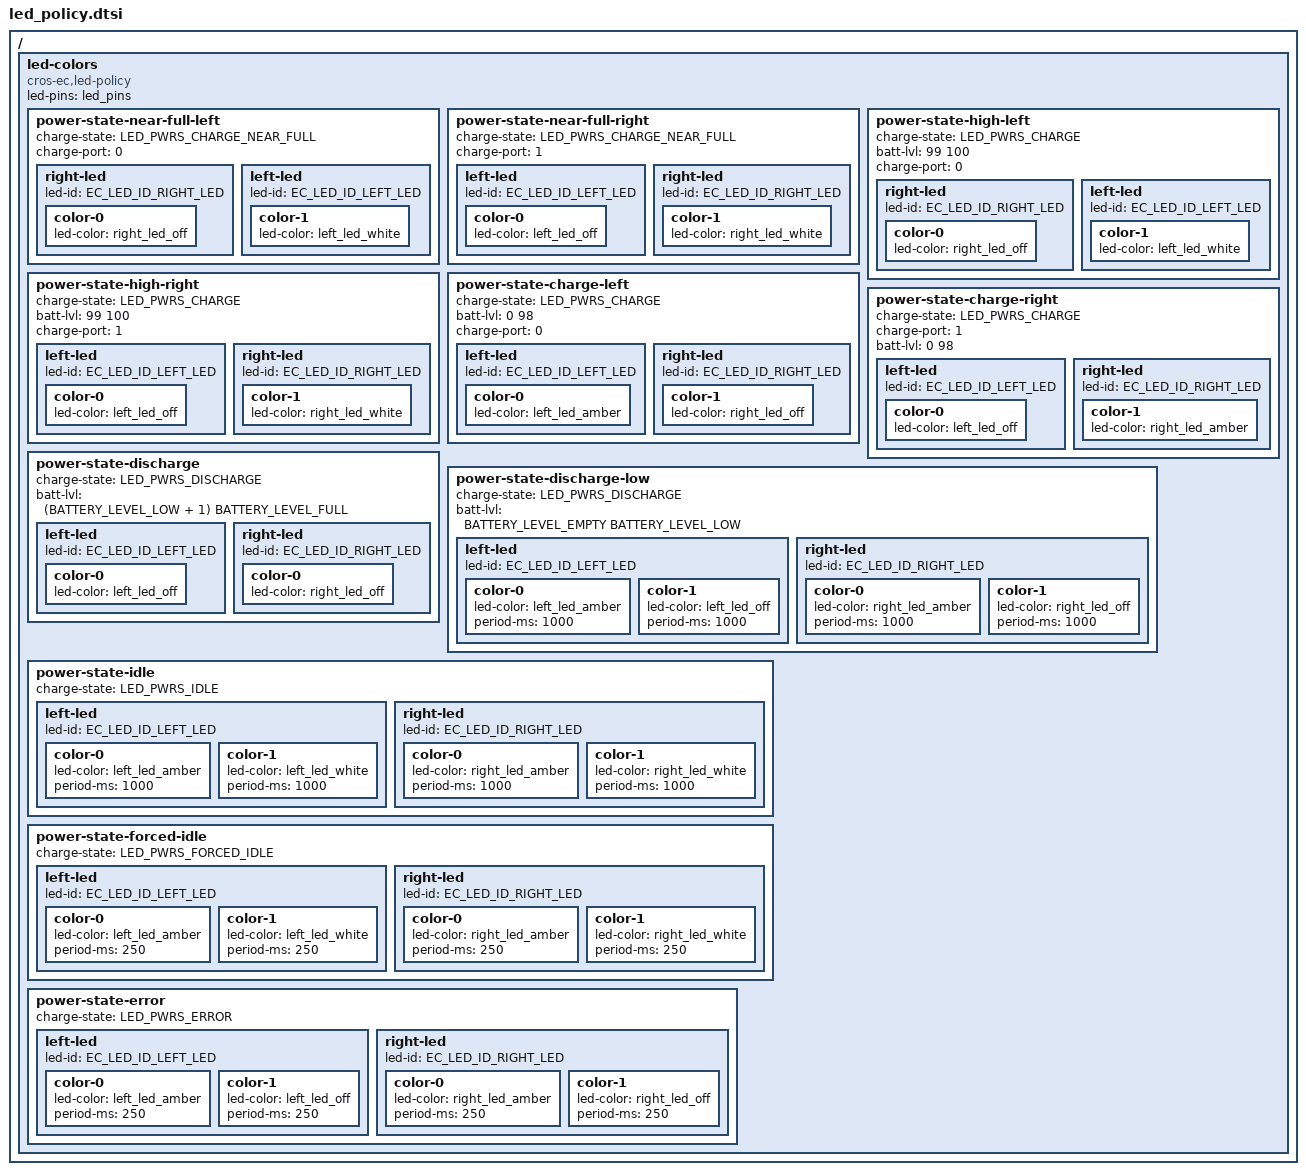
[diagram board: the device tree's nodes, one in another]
#include <dt-bindings/battery.h>

/ {
	led-colors {
		compatible = "cros-ec,led-policy";
		led-pins = <&led_pins>;

		power-state-near-full-left {
			charge-state = "LED_PWRS_CHARGE_NEAR_FULL";
			charge-port = <0>; /* Left port */

			right-led {
				led-id = "EC_LED_ID_RIGHT_LED";

				/* Turn off the right LED */
				color-0 {
					led-color = <&right_led_off>;
				};
			};

			left-led {
				led-id = "EC_LED_ID_LEFT_LED";
				/* Left LED to White */
				color-1 {
					led-color = <&left_led_white>;
				};
			};
		};

		power-state-near-full-right {
			charge-state = "LED_PWRS_CHARGE_NEAR_FULL";
			charge-port = <1>; /* Right port */

			left-led {
				led-id = "EC_LED_ID_LEFT_LED";

				/* Turn off the left LED */
				color-0 {
					led-color = <&left_led_off>;
				};
			};

			right-led {
				led-id = "EC_LED_ID_RIGHT_LED";
				/* Right LED to White */
				color-1 {
					led-color = <&right_led_white>;
				};
			};
		};

		power-state-high-left {
			charge-state = "LED_PWRS_CHARGE";
			/* Battery percent range 99..100 */
			batt-lvl = <99 100>;

			charge-port = <0>; /* Left port */

			right-led {
				led-id = "EC_LED_ID_RIGHT_LED";

				/* Turn off the right LED */
				color-0 {
					led-color = <&right_led_off>;
				};
			};

			left-led {
				led-id = "EC_LED_ID_LEFT_LED";
				/* Left LED to White */
				color-1 {
					led-color = <&left_led_white>;
				};
			};
		};

		power-state-high-right {
			charge-state = "LED_PWRS_CHARGE";
			/* Battery percent range 99..100 */
			batt-lvl = <99 100>;
			charge-port = <1>; /* Right port */

			left-led {
				led-id = "EC_LED_ID_LEFT_LED";

				/* Turn off the left LED */
				color-0 {
					led-color = <&left_led_off>;
				};
			};

			right-led {
				led-id = "EC_LED_ID_RIGHT_LED";
				/* Right LED to White */
				color-1 {
					led-color = <&right_led_white>;
				};
			};
		};

		power-state-charge-left {
			charge-state = "LED_PWRS_CHARGE";
			/* Battery percent range 0..98 */
			batt-lvl = <0 98>;
			charge-port = <0>; /* Left port */

			left-led {
				led-id = "EC_LED_ID_LEFT_LED";

				/* Left LED to Amber */
				color-0 {
					led-color = <&left_led_amber>;
				};
			};

			right-led {
				led-id = "EC_LED_ID_RIGHT_LED";
				/* Turn off the right LED */
				color-1 {
					led-color = <&right_led_off>;
				};
			};
		};

		power-state-charge-right {
			charge-state = "LED_PWRS_CHARGE";
			charge-port = <1>; /* Right port */
			/* Battery percent range 0..98 */
			batt-lvl = <0 98>;

			left-led {
				led-id = "EC_LED_ID_LEFT_LED";

				/* Turn off the left LED */
				color-0 {
					led-color = <&left_led_off>;
				};
			};

			right-led {
				led-id = "EC_LED_ID_RIGHT_LED";
				/* Right LED to Amber */
				color-1 {
					led-color = <&right_led_amber>;
				};
			};
		};

		power-state-discharge {
			charge-state = "LED_PWRS_DISCHARGE";
			/* Battery percent range (> Low, <= Full) */
			batt-lvl = <(BATTERY_LEVEL_LOW + 1) BATTERY_LEVEL_FULL>;

			/* Turn off both LEDs LED */
			left-led {
				led-id = "EC_LED_ID_LEFT_LED";

				color-0 {
					led-color = <&left_led_off>;
				};
			};

			right-led {
				led-id = "EC_LED_ID_RIGHT_LED";

				color-0 {
					led-color = <&right_led_off>;
				};
			};
		};

		power-state-discharge-low {
			charge-state = "LED_PWRS_DISCHARGE";
			/* Battery percent range (>= Empty, <= Low) */
			batt-lvl = <BATTERY_LEVEL_EMPTY BATTERY_LEVEL_LOW>;

			/* Blink both LEDs amber at 0.5 Hz */
			left-led {
				led-id = "EC_LED_ID_LEFT_LED";

				color-0 {
					led-color = <&left_led_amber>;
					period-ms = <1000>;
				};
				color-1 {
					led-color = <&left_led_off>;
					period-ms = <1000>;
				};
			};

			right-led {
				led-id = "EC_LED_ID_RIGHT_LED";

				color-0 {
					led-color = <&right_led_amber>;
					period-ms = <1000>;
				};
				color-1 {
					led-color = <&right_led_off>;
					period-ms = <1000>;
				};
			};
		};

		power-state-idle {
			charge-state = "LED_PWRS_IDLE";

			/* Blink both LEDs amber at 0.5 Hz */
			left-led {
				led-id = "EC_LED_ID_LEFT_LED";

				color-0 {
					led-color = <&left_led_amber>;
					period-ms = <1000>;
				};
				color-1 {
					led-color = <&left_led_white>;
					period-ms = <1000>;
				};
			};

			right-led {
				led-id = "EC_LED_ID_RIGHT_LED";

				color-0 {
					led-color = <&right_led_amber>;
					period-ms = <1000>;
				};
				color-1 {
					led-color = <&right_led_white>;
					period-ms = <1000>;
				};
			};
		};

		power-state-forced-idle {
			charge-state = "LED_PWRS_FORCED_IDLE";

			/* Blink both LEDs amber at 2 Hz */
			left-led {
				led-id = "EC_LED_ID_LEFT_LED";

				color-0 {
					led-color = <&left_led_amber>;
					period-ms = <250>;
				};
				color-1 {
					led-color = <&left_led_white>;
					period-ms = <250>;
				};
			};

			right-led {
				led-id = "EC_LED_ID_RIGHT_LED";

				color-0 {
					led-color = <&right_led_amber>;
					period-ms = <250>;
				};
				color-1 {
					led-color = <&right_led_white>;
					period-ms = <250>;
				};
			};
		};

		power-state-error {
			charge-state = "LED_PWRS_ERROR";

			/* Blink both LEDs amber at 2 Hz */
			left-led {
				led-id = "EC_LED_ID_LEFT_LED";

				color-0 {
					led-color = <&left_led_amber>;
					period-ms = <250>;
				};
				color-1 {
					led-color = <&left_led_off>;
					period-ms = <250>;
				};
			};

			right-led {
				led-id = "EC_LED_ID_RIGHT_LED";

				color-0 {
					led-color = <&right_led_amber>;
					period-ms = <250>;
				};
				color-1 {
					led-color = <&right_led_off>;
					period-ms = <250>;
				};
			};
		};
	};
};
